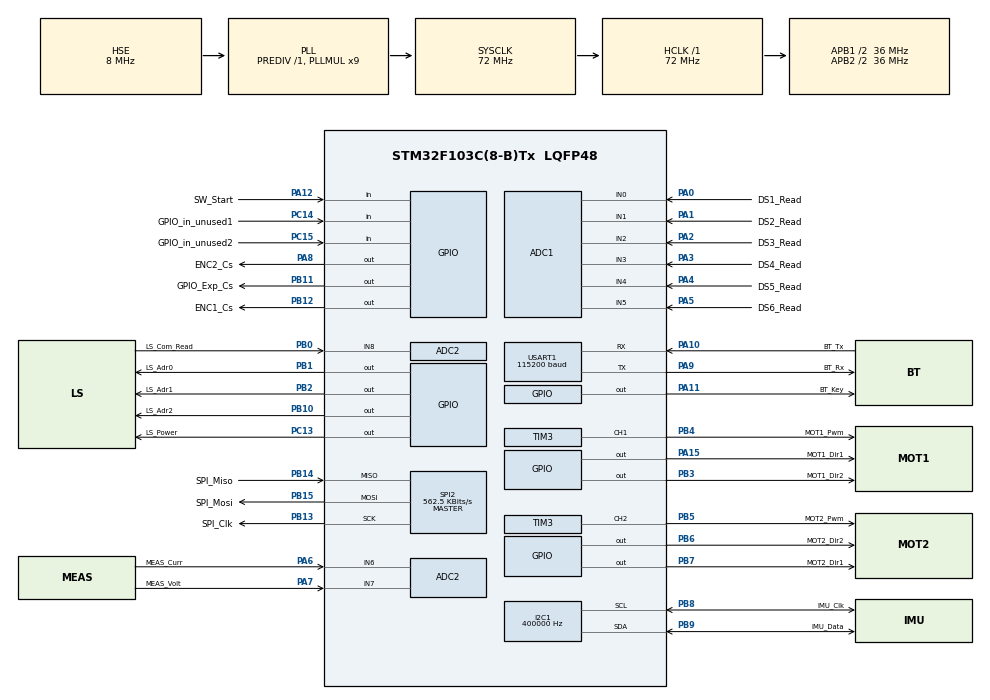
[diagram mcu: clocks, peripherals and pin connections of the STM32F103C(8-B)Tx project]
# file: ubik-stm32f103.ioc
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ADC1.Channel-48\#ChannelRegularConversion=ADC_CHANNEL_0
ADC1.Channel-49\#ChannelRegularConversion=ADC_CHANNEL_1
ADC1.Channel-50\#ChannelRegularConversion=ADC_CHANNEL_2
ADC1.Channel-51\#ChannelRegularConversion=ADC_CHANNEL_3
ADC1.Channel-52\#ChannelRegularConversion=ADC_CHANNEL_4
ADC1.Channel-53\#ChannelRegularConversion=ADC_CHANNEL_5
ADC1.ContinuousConvMode=DISABLE
ADC1.DataAlign=ADC_DATAALIGN_RIGHT
ADC1.DiscontinuousConvMode=DISABLE
ADC1.EnableAnalogWatchDog=false
ADC1.EnableRegularConversion=ENABLE
ADC1.ExternalTrigConv=ADC_SOFTWARE_START
ADC1.InjNumberOfConversion=0
ADC1.NbrOfConversion=6
ADC1.NbrOfConversionFlag=1
ADC1.Rank-48\#ChannelRegularConversion=1
ADC1.Rank-49\#ChannelRegularConversion=2
ADC1.Rank-50\#ChannelRegularConversion=3
ADC1.Rank-51\#ChannelRegularConversion=4
ADC1.Rank-52\#ChannelRegularConversion=5
ADC1.Rank-53\#ChannelRegularConversion=6
ADC1.SamplingTime-48\#ChannelRegularConversion=ADC_SAMPLETIME_28CYCLES_5
ADC1.SamplingTime-49\#ChannelRegularConversion=ADC_SAMPLETIME_28CYCLES_5
ADC1.SamplingTime-50\#ChannelRegularConversion=ADC_SAMPLETIME_28CYCLES_5
ADC1.SamplingTime-51\#ChannelRegularConversion=ADC_SAMPLETIME_28CYCLES_5
ADC1.SamplingTime-52\#ChannelRegularConversion=ADC_SAMPLETIME_28CYCLES_5
ADC1.SamplingTime-53\#ChannelRegularConversion=ADC_SAMPLETIME_28CYCLES_5
ADC1.ScanConvMode=ADC_SCAN_ENABLE
ADC1.master=1
ADC2.Channel-41\#ChannelRegularConversion=ADC_CHANNEL_6
ADC2.Channel-42\#ChannelRegularConversion=ADC_CHANNEL_7
ADC2.Channel-47\#ChannelInjectedConversion=ADC_CHANNEL_8
ADC2.ContinuousConvMode=DISABLE
ADC2.DataAlign=ADC_DATAALIGN_RIGHT
ADC2.DiscontinuousConvMode=ENABLE
ADC2.EnableAnalogWatchDog=false
ADC2.EnableRegularConversion=ENABLE
ADC2.ExternalTrigConv=ADC_SOFTWARE_START
ADC2.ExternalTrigInjecConv=ADC_INJECTED_SOFTWARE_START
ADC2.InjNumberOfConversion=1
ADC2.InjectedConvMode=None
ADC2.InjectedOffset-47\#ChannelInjectedConversion=0
ADC2.NbrOfConversion=2
ADC2.NbrOfConversionFlag=1
ADC2.NbrOfDiscConversion=1
ADC2.Rank-41\#ChannelRegularConversion=1
ADC2.Rank-42\#ChannelRegularConversion=2
ADC2.Rank-47\#ChannelInjectedConversion=1
ADC2.SamplingTime-41\#ChannelRegularConversion=ADC_SAMPLETIME_239CYCLES_5
ADC2.SamplingTime-42\#ChannelRegularConversion=ADC_SAMPLETIME_239CYCLES_5
ADC2.SamplingTime-47\#ChannelInjectedConversion=ADC_SAMPLETIME_13CYCLES_5
ADC2.ScanConvMode=ADC_SCAN_ENABLE
Dma.ADC1.2.Direction=DMA_PERIPH_TO_MEMORY
Dma.ADC1.2.Instance=DMA1_Channel1
Dma.ADC1.2.MemDataAlignment=DMA_MDATAALIGN_HALFWORD
Dma.ADC1.2.MemInc=DMA_MINC_ENABLE
Dma.ADC1.2.Mode=DMA_NORMAL
Dma.ADC1.2.PeriphDataAlignment=DMA_PDATAALIGN_HALFWORD
Dma.ADC1.2.PeriphInc=DMA_PINC_DISABLE
Dma.ADC1.2.Priority=DMA_PRIORITY_MEDIUM
Dma.I2C1_RX.0.Direction=DMA_PERIPH_TO_MEMORY
Dma.I2C1_RX.0.Instance=DMA1_Channel7
Dma.I2C1_RX.0.MemDataAlignment=DMA_MDATAALIGN_BYTE
Dma.I2C1_RX.0.MemInc=DMA_MINC_ENABLE
Dma.I2C1_RX.0.Mode=DMA_NORMAL
Dma.I2C1_RX.0.PeriphDataAlignment=DMA_PDATAALIGN_BYTE
Dma.I2C1_RX.0.PeriphInc=DMA_PINC_DISABLE
Dma.I2C1_RX.0.Priority=DMA_PRIORITY_HIGH
Dma.I2C1_TX.1.Direction=DMA_MEMORY_TO_PERIPH
Dma.I2C1_TX.1.Instance=DMA1_Channel6
Dma.I2C1_TX.1.MemDataAlignment=DMA_MDATAALIGN_BYTE
Dma.I2C1_TX.1.MemInc=DMA_MINC_ENABLE
Dma.I2C1_TX.1.Mode=DMA_NORMAL
Dma.I2C1_TX.1.PeriphDataAlignment=DMA_PDATAALIGN_BYTE
Dma.I2C1_TX.1.PeriphInc=DMA_PINC_DISABLE
Dma.I2C1_TX.1.Priority=DMA_PRIORITY_HIGH
Dma.Request0=I2C1_RX
Dma.Request1=I2C1_TX
Dma.Request2=ADC1
Dma.Request3=USART1_RX
Dma.Request4=USART1_TX
Dma.USART1_RX.3.Direction=DMA_PERIPH_TO_MEMORY
Dma.USART1_RX.3.Instance=DMA1_Channel5
Dma.USART1_RX.3.MemDataAlignment=DMA_MDATAALIGN_BYTE
Dma.USART1_RX.3.MemInc=DMA_MINC_ENABLE
Dma.USART1_RX.3.Mode=DMA_NORMAL
Dma.USART1_RX.3.PeriphDataAlignment=DMA_PDATAALIGN_BYTE
Dma.USART1_RX.3.PeriphInc=DMA_PINC_DISABLE
Dma.USART1_RX.3.Priority=DMA_PRIORITY_LOW
Dma.USART1_TX.4.Direction=DMA_MEMORY_TO_PERIPH
Dma.USART1_TX.4.Instance=DMA1_Channel4
Dma.USART1_TX.4.MemDataAlignment=DMA_MDATAALIGN_BYTE
Dma.USART1_TX.4.MemInc=DMA_MINC_ENABLE
Dma.USART1_TX.4.Mode=DMA_NORMAL
Dma.USART1_TX.4.PeriphDataAlignment=DMA_PDATAALIGN_BYTE
Dma.USART1_TX.4.PeriphInc=DMA_PINC_DISABLE
Dma.USART1_TX.4.Priority=DMA_PRIORITY_LOW
I2C1.ClockSpeed=400000
I2C1.DutyCycle=I2C_DUTYCYCLE_2
I2C1.I2C_Mode=I2C_Fast
Mcu.Family=STM32F1
Mcu.Name=STM32F103C(8-B)Tx
Mcu.Package=LQFP48
NVIC.DMA1_Channel1_IRQn=true\:7\:0\:true\:false\:true\:true
NVIC.DMA1_Channel4_IRQn=true\:9\:0\:true\:false\:true\:true
NVIC.DMA1_Channel5_IRQn=true\:9\:0\:true\:false\:true\:true
NVIC.DMA1_Channel6_IRQn=true\:6\:0\:true\:false\:true\:true
NVIC.DMA1_Channel7_IRQn=true\:6\:0\:true\:false\:true\:true
NVIC.PriorityGroup=NVIC_PRIORITYGROUP_4
NVIC.TIM1_UP_IRQn=true\:0\:0\:false\:false\:true\:true
NVIC.TIM2_IRQn=true\:7\:0\:true\:false\:true\:true
NVIC.TIM4_IRQn=true\:8\:0\:true\:false\:true\:true
NVIC.TimeBase=TIM1_UP_IRQn
NVIC.TimeBaseIP=TIM1
NVIC.USART1_IRQn=true\:10\:0\:true\:false\:true\:true
PA0-WKUP.GPIO_Label=DS1_Read
PA0-WKUP.Signal=ADCx_IN0
PA1.GPIO_Label=DS2_Read
PA1.Signal=ADCx_IN1
PA10.GPIO_Label=BT_Tx
PA10.Mode=Asynchronous
PA10.Signal=USART1_RX
PA11.GPIO_Label=BT_Key
PA11.PinState=GPIO_PIN_SET
PA11.Signal=GPIO_Output
PA12.GPIO_Label=SW_Start
PA12.GPIO_PuPd=GPIO_PULLDOWN
PA12.Signal=GPIO_Input
PA13.GPIO_Label=SWD_IO
PA13.Mode=Serial_Wire
PA13.Signal=SYS_JTMS-SWDIO
PA14.GPIO_Label=SDW_CLK
PA14.Mode=Serial_Wire
PA14.Signal=SYS_JTCK-SWCLK
PA15.GPIO_Label=MOT1_Dir1
PA15.Signal=GPIO_Output
PA2.GPIO_Label=DS3_Read
PA2.Signal=ADCx_IN2
PA3.GPIO_Label=DS4_Read
PA3.Signal=ADCx_IN3
PA4.GPIO_Label=DS5_Read
PA4.Signal=ADCx_IN4
PA5.GPIO_Label=DS6_Read
PA5.Signal=ADCx_IN5
PA6.GPIO_Label=MEAS_Curr
PA6.Signal=ADCx_IN6
PA7.GPIO_Label=MEAS_Volt
PA7.Signal=ADCx_IN7
PA8.GPIO_Label=ENC2_Cs
PA8.GPIO_Speed=GPIO_SPEED_FREQ_HIGH
PA8.PinState=GPIO_PIN_SET
PA8.Signal=GPIO_Output
PA9.GPIO_Label=BT_Rx
PA9.Mode=Asynchronous
PA9.Signal=USART1_TX
PB0.GPIO_Label=LS_Com_Read
PB0.Signal=ADCx_IN8
PB1.GPIO_Label=LS_Adr0
PB1.Signal=GPIO_Output
PB10.GPIO_Label=LS_Adr2
PB10.Signal=GPIO_Output
PB11.GPIO_Label=GPIO_Exp_Cs
PB11.GPIO_Speed=GPIO_SPEED_FREQ_HIGH
PB11.PinState=GPIO_PIN_SET
PB11.Signal=GPIO_Output
PB12.GPIO_Label=ENC1_Cs
PB12.PinState=GPIO_PIN_SET
PB12.Signal=GPIO_Output
PB13.GPIO_Label=SPI_Clk
PB13.Mode=Full_Duplex_Master
PB13.Signal=SPI2_SCK
PB14.GPIO_Label=SPI_Miso
PB14.Mode=Full_Duplex_Master
PB14.Signal=SPI2_MISO
PB15.GPIO_Label=SPI_Mosi
PB15.Mode=Full_Duplex_Master
PB15.Signal=SPI2_MOSI
PB2.GPIO_Label=LS_Adr1
PB2.Signal=GPIO_Output
PB3.GPIO_Label=MOT1_Dir2
PB3.Signal=GPIO_Output
PB4.GPIO_Label=MOT1_Pwm
PB4.Signal=S_TIM3_CH1
PB5.GPIO_Label=MOT2_Pwm
PB5.GPIO_Speed=GPIO_SPEED_FREQ_LOW
PB5.Signal=S_TIM3_CH2
PB6.GPIO_Label=MOT2_Dir2
PB6.Signal=GPIO_Output
PB7.GPIO_Label=MOT2_Dir1
PB7.Signal=GPIO_Output
PB8.GPIO_Label=IMU_Clk
PB8.Mode=I2C
PB8.Signal=I2C1_SCL
PB9.GPIO_Label=IMU_Data
PB9.Mode=I2C
PB9.Signal=I2C1_SDA
PC13-TAMPER-RTC.GPIO_Label=LS_Power
PC13-TAMPER-RTC.Signal=GPIO_Output
PC14-OSC32_IN.GPIO_Label=GPIO_in_unused1
PC14-OSC32_IN.GPIO_PuPd=GPIO_PULLUP
PC14-OSC32_IN.Signal=GPIO_Input
PC15-OSC32_OUT.GPIO_Label=GPIO_in_unused2
PC15-OSC32_OUT.GPIO_PuPd=GPIO_PULLUP
PC15-OSC32_OUT.Signal=GPIO_Input
PD0-OSC_IN.Mode=HSE-External-Oscillator
PD0-OSC_IN.Signal=RCC_OSC_IN
PD1-OSC_OUT.Mode=HSE-External-Oscillator
PD1-OSC_OUT.Signal=RCC_OSC_OUT
ProjectManager.HeapSize=0x200
ProjectManager.StackSize=0x400
ProjectManager.TargetToolchain=SW4STM32
RCC.ADCPresc=RCC_ADCPCLK2_DIV4
RCC.AHBFreq_Value=72000000
RCC.APB1CLKDivider=RCC_HCLK_DIV2
RCC.APB1Freq_Value=36000000
RCC.APB1TimFreq_Value=72000000
RCC.APB2CLKDivider=RCC_HCLK_DIV2
RCC.APB2Freq_Value=36000000
RCC.APB2TimFreq_Value=72000000
RCC.HCLKFreq_Value=72000000
RCC.PLLMUL=RCC_PLL_MUL9
RCC.PLLSourceVirtual=RCC_PLLSOURCE_HSE
RCC.SYSCLKFreq_VALUE=72000000
RCC.SYSCLKSource=RCC_SYSCLKSOURCE_PLLCLK
RCC.USBFreq_Value=72000000
RCC.VDD_VALUE=3.3
SH.ADCx_IN0.0=ADC1_IN0,IN0
SH.ADCx_IN1.0=ADC1_IN1,IN1
SH.ADCx_IN2.0=ADC1_IN2,IN2
SH.ADCx_IN3.0=ADC1_IN3,IN3
SH.ADCx_IN4.0=ADC1_IN4,IN4
SH.ADCx_IN5.0=ADC1_IN5,IN5
SH.ADCx_IN6.0=ADC2_IN6,IN6
SH.ADCx_IN7.0=ADC2_IN7,IN7
SH.ADCx_IN8.0=ADC2_IN8,IN8
SH.S_TIM3_CH1.0=TIM3_CH1,PWM Generation1 CH1
SH.S_TIM3_CH2.0=TIM3_CH2,PWM Generation2 CH2
SPI2.BaudRatePrescaler=SPI_BAUDRATEPRESCALER_64
SPI2.CLKPhase=SPI_PHASE_1EDGE
SPI2.CLKPolarity=SPI_POLARITY_HIGH
SPI2.CalculateBaudRate=562.5 KBits/s
SPI2.Direction=SPI_DIRECTION_2LINES
SPI2.Mode=SPI_MODE_MASTER
SPI2.VirtualType=VM_MASTER
TIM2.Prescaler=72 - 1
TIM2.TIM_MasterOutputTrigger=TIM_TRGO_RESET
TIM3.Channel-PWM\ Generation1\ CH1=TIM_CHANNEL_1
TIM3.Channel-PWM\ Generation2\ CH2=TIM_CHANNEL_2
TIM3.Period=7200 - 1
TIM3.Prescaler=0
TIM4.Period=250 - 1
TIM4.Prescaler=72 - 1
USART1.BaudRate=115200
USART1.VirtualMode=VM_ASYNC
VP_SYS_VS_tim1.Mode=TIM1
VP_TIM2_VS_ClockSourceINT.Mode=Internal
VP_TIM4_VS_ClockSourceINT.Mode=Internal
board=ubik-stm32f103

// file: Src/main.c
/**
  ******************************************************************************
  * @file           : main.c
  * @brief          : Main program body
  ******************************************************************************
  ** This notice applies to any and all portions of this file
  * that are not between comment pairs USER CODE BEGIN and
  * USER CODE END. Other portions of this file, whether
  * inserted by the user or by software development tools
  * are owned by their respective copyright owners.
  *
  * COPYRIGHT(c) 2018 STMicroelectronics
  *
  * Redistribution and use in source and binary forms, with or without modification,
  * are permitted provided that the following conditions are met:
  *   1. Redistributions of source code must retain the above copyright notice,
  *      this list of conditions and the following disclaimer.
  *   2. Redistributions in binary form must reproduce the above copyright notice,
  *      this list of conditions and the following disclaimer in the documentation
  *      and/or other materials provided with the distribution.
  *   3. Neither the name of STMicroelectronics nor the names of its contributors
  *      may be used to endorse or promote products derived from this software
  *      without specific prior written permission.
  *
  * THIS SOFTWARE IS PROVIDED BY THE COPYRIGHT HOLDERS AND CONTRIBUTORS "AS IS"
  * AND ANY EXPRESS OR IMPLIED WARRANTIES, INCLUDING, BUT NOT LIMITED TO, THE
  * IMPLIED WARRANTIES OF MERCHANTABILITY AND FITNESS FOR A PARTICULAR PURPOSE ARE
  * DISCLAIMED. IN NO EVENT SHALL THE COPYRIGHT HOLDER OR CONTRIBUTORS BE LIABLE
  * FOR ANY DIRECT, INDIRECT, INCIDENTAL, SPECIAL, EXEMPLARY, OR CONSEQUENTIAL
  * DAMAGES (INCLUDING, BUT NOT LIMITED TO, PROCUREMENT OF SUBSTITUTE GOODS OR
  * SERVICES; LOSS OF USE, DATA, OR PROFITS; OR BUSINESS INTERRUPTION) HOWEVER
  * CAUSED AND ON ANY THEORY OF LIABILITY, WHETHER IN CONTRACT, STRICT LIABILITY,
  * OR TORT (INCLUDING NEGLIGENCE OR OTHERWISE) ARISING IN ANY WAY OUT OF THE USE
  * OF THIS SOFTWARE, EVEN IF ADVISED OF THE POSSIBILITY OF SUCH DAMAGE.
  *
  ******************************************************************************
  */
#include "main.h"
#include "stm32f1xx_hal.h"

ADC_HandleTypeDef hadc1;
ADC_HandleTypeDef hadc2;
DMA_HandleTypeDef hdma_adc1;

I2C_HandleTypeDef hi2c1;
DMA_HandleTypeDef hdma_i2c1_rx;
DMA_HandleTypeDef hdma_i2c1_tx;

SPI_HandleTypeDef hspi2;

TIM_HandleTypeDef htim2;
TIM_HandleTypeDef htim3;
TIM_HandleTypeDef htim4;

UART_HandleTypeDef huart1;
DMA_HandleTypeDef hdma_usart1_rx;
DMA_HandleTypeDef hdma_usart1_tx;

/* USER CODE BEGIN PV */
/* Private variables ---------------------------------------------------------*/

/* USER CODE END PV */

void SystemClock_Config(void);
static void MX_GPIO_Init(void);
static void MX_DMA_Init(void);
static void MX_SPI2_Init(void);
static void MX_TIM3_Init(void);
static void MX_USART1_UART_Init(void);
static void MX_ADC2_Init(void);
static void MX_ADC1_Init(void);
static void MX_TIM2_Init(void);
static void MX_I2C1_Init(void);
static void MX_TIM4_Init(void);

void HAL_TIM_MspPostInit(TIM_HandleTypeDef *htim);

/* USER CODE BEGIN PFP */
/* Private function prototypes -----------------------------------------------*/

/* USER CODE END PFP */

int main(void)
{

  /* MCU Configuration----------------------------------------------------------*/

  /* Reset of all peripherals, Initializes the Flash interface and the Systick. */
  HAL_Init();

  /* Configure the system clock */
  SystemClock_Config();

   /* USER CODE BEGIN SysInit */

  /* Disable SysTick before it shoots!
   *
   * In FreeRTOSConfig.h SysTick_Handler is mapped to xPortSysTickHandler
   * so we cannot let SysTick fire its interrupt before starting FreeRTOS
   * scheduler. In Cube we changed System Timebase to some other timer, so
   * we can safely disable SysTick here. FreeRTOS will configure it when
   * it starts.  */
  CLEAR_BIT(SysTick->CTRL, SysTick_CTRL_ENABLE_Msk);

  /* USER CODE END SysInit */

  /* Initialize all configured peripherals */
  MX_GPIO_Init();
  MX_DMA_Init();
  MX_SPI2_Init();
  MX_TIM3_Init();
  MX_USART1_UART_Init();
  MX_ADC2_Init();
  MX_ADC1_Init();
  MX_TIM2_Init();
  MX_I2C1_Init();
  MX_TIM4_Init();
  /* USER CODE BEGIN 2 */

  /* Pass control to extern_main() defined somewhere else with C linkage */
  extern void extern_main(void);
  extern_main();

  /* Execution should never get here */
  Error_Handler();

  /* USER CODE END 2 */

  /* Infinite loop */
  while (1)
  {

  }

}

void SystemClock_Config(void)
{

  RCC_OscInitTypeDef RCC_OscInitStruct;
  RCC_ClkInitTypeDef RCC_ClkInitStruct;
  RCC_PeriphCLKInitTypeDef PeriphClkInit;

    /**Initializes the CPU, AHB and APB busses clocks
    */
  RCC_OscInitStruct.OscillatorType = RCC_OSCILLATORTYPE_HSE;
  RCC_OscInitStruct.HSEState = RCC_HSE_ON;
  RCC_OscInitStruct.HSEPredivValue = RCC_HSE_PREDIV_DIV1;
  RCC_OscInitStruct.HSIState = RCC_HSI_ON;
  RCC_OscInitStruct.PLL.PLLState = RCC_PLL_ON;
  RCC_OscInitStruct.PLL.PLLSource = RCC_PLLSOURCE_HSE;
  RCC_OscInitStruct.PLL.PLLMUL = RCC_PLL_MUL9;
  if (HAL_RCC_OscConfig(&RCC_OscInitStruct) != HAL_OK)
  {
    _Error_Handler(__FILE__, __LINE__);
  }

    /**Initializes the CPU, AHB and APB busses clocks
    */
  RCC_ClkInitStruct.ClockType = RCC_CLOCKTYPE_HCLK|RCC_CLOCKTYPE_SYSCLK
                              |RCC_CLOCKTYPE_PCLK1|RCC_CLOCKTYPE_PCLK2;
  RCC_ClkInitStruct.SYSCLKSource = RCC_SYSCLKSOURCE_PLLCLK;
  RCC_ClkInitStruct.AHBCLKDivider = RCC_SYSCLK_DIV1;
  RCC_ClkInitStruct.APB1CLKDivider = RCC_HCLK_DIV2;
  RCC_ClkInitStruct.APB2CLKDivider = RCC_HCLK_DIV2;

  if (HAL_RCC_ClockConfig(&RCC_ClkInitStruct, FLASH_LATENCY_2) != HAL_OK)
  {
    _Error_Handler(__FILE__, __LINE__);
  }

  PeriphClkInit.PeriphClockSelection = RCC_PERIPHCLK_ADC;
  PeriphClkInit.AdcClockSelection = RCC_ADCPCLK2_DIV4;
  if (HAL_RCCEx_PeriphCLKConfig(&PeriphClkInit) != HAL_OK)
  {
    _Error_Handler(__FILE__, __LINE__);
  }

    /**Configure the Systick interrupt time
    */
  HAL_SYSTICK_Config(HAL_RCC_GetHCLKFreq()/1000);

    /**Configure the Systick
    */
  HAL_SYSTICK_CLKSourceConfig(SYSTICK_CLKSOURCE_HCLK);

  /* SysTick_IRQn interrupt configuration */
  HAL_NVIC_SetPriority(SysTick_IRQn, 0, 0);
}

/* ADC1 init function */
static void MX_ADC1_Init(void)
{

  ADC_ChannelConfTypeDef sConfig;

    /**Common config
    */
  hadc1.Instance = ADC1;
  hadc1.Init.ScanConvMode = ADC_SCAN_ENABLE;
  hadc1.Init.ContinuousConvMode = DISABLE;
  hadc1.Init.DiscontinuousConvMode = DISABLE;
  hadc1.Init.ExternalTrigConv = ADC_SOFTWARE_START;
  hadc1.Init.DataAlign = ADC_DATAALIGN_RIGHT;
  hadc1.Init.NbrOfConversion = 6;
  if (HAL_ADC_Init(&hadc1) != HAL_OK)
  {
    _Error_Handler(__FILE__, __LINE__);
  }

    /**Configure Regular Channel
    */
  sConfig.Channel = ADC_CHANNEL_0;
  sConfig.Rank = ADC_REGULAR_RANK_1;
  sConfig.SamplingTime = ADC_SAMPLETIME_28CYCLES_5;
  if (HAL_ADC_ConfigChannel(&hadc1, &sConfig) != HAL_OK)
  {
    _Error_Handler(__FILE__, __LINE__);
  }

    /**Configure Regular Channel
    */
  sConfig.Channel = ADC_CHANNEL_1;
  sConfig.Rank = ADC_REGULAR_RANK_2;
  if (HAL_ADC_ConfigChannel(&hadc1, &sConfig) != HAL_OK)
  {
    _Error_Handler(__FILE__, __LINE__);
  }

    /**Configure Regular Channel
    */
  sConfig.Channel = ADC_CHANNEL_2;
  sConfig.Rank = ADC_REGULAR_RANK_3;
  if (HAL_ADC_ConfigChannel(&hadc1, &sConfig) != HAL_OK)
  {
    _Error_Handler(__FILE__, __LINE__);
  }

    /**Configure Regular Channel
    */
  sConfig.Channel = ADC_CHANNEL_3;
  sConfig.Rank = ADC_REGULAR_RANK_4;
  if (HAL_ADC_ConfigChannel(&hadc1, &sConfig) != HAL_OK)
  {
    _Error_Handler(__FILE__, __LINE__);
  }

    /**Configure Regular Channel
    */
  sConfig.Channel = ADC_CHANNEL_4;
  sConfig.Rank = ADC_REGULAR_RANK_5;
  if (HAL_ADC_ConfigChannel(&hadc1, &sConfig) != HAL_OK)
  {
    _Error_Handler(__FILE__, __LINE__);
  }

    /**Configure Regular Channel
    */
  sConfig.Channel = ADC_CHANNEL_5;
  sConfig.Rank = ADC_REGULAR_RANK_6;
  if (HAL_ADC_ConfigChannel(&hadc1, &sConfig) != HAL_OK)
  {
    _Error_Handler(__FILE__, __LINE__);
  }

}

/* ADC2 init function */
static void MX_ADC2_Init(void)
{

  ADC_ChannelConfTypeDef sConfig;
  ADC_InjectionConfTypeDef sConfigInjected;

    /**Common config
    */
  hadc2.Instance = ADC2;
  hadc2.Init.ScanConvMode = ADC_SCAN_ENABLE;
  hadc2.Init.ContinuousConvMode = DISABLE;
  hadc2.Init.DiscontinuousConvMode = ENABLE;
  hadc2.Init.NbrOfDiscConversion = 1;
  hadc2.Init.ExternalTrigConv = ADC_SOFTWARE_START;
  hadc2.Init.DataAlign = ADC_DATAALIGN_RIGHT;
  hadc2.Init.NbrOfConversion = 2;
  if (HAL_ADC_Init(&hadc2) != HAL_OK)
  {
    _Error_Handler(__FILE__, __LINE__);
  }

    /**Configure Regular Channel
    */
  sConfig.Channel = ADC_CHANNEL_6;
  sConfig.Rank = ADC_REGULAR_RANK_1;
  sConfig.SamplingTime = ADC_SAMPLETIME_239CYCLES_5;
  if (HAL_ADC_ConfigChannel(&hadc2, &sConfig) != HAL_OK)
  {
    _Error_Handler(__FILE__, __LINE__);
  }

    /**Configure Regular Channel
    */
  sConfig.Channel = ADC_CHANNEL_7;
  sConfig.Rank = ADC_REGULAR_RANK_2;
  if (HAL_ADC_ConfigChannel(&hadc2, &sConfig) != HAL_OK)
  {
    _Error_Handler(__FILE__, __LINE__);
  }

    /**Configure Injected Channel
    */
  sConfigInjected.InjectedChannel = ADC_CHANNEL_8;
  sConfigInjected.InjectedRank = ADC_INJECTED_RANK_1;
  sConfigInjected.InjectedNbrOfConversion = 1;
  sConfigInjected.InjectedSamplingTime = ADC_SAMPLETIME_13CYCLES_5;
  sConfigInjected.ExternalTrigInjecConv = ADC_INJECTED_SOFTWARE_START;
  sConfigInjected.AutoInjectedConv = DISABLE;
  sConfigInjected.InjectedDiscontinuousConvMode = DISABLE;
  sConfigInjected.InjectedOffset = 0;
  if (HAL_ADCEx_InjectedConfigChannel(&hadc2, &sConfigInjected) != HAL_OK)
  {
    _Error_Handler(__FILE__, __LINE__);
  }

}

/* I2C1 init function */
static void MX_I2C1_Init(void)
{

  hi2c1.Instance = I2C1;
  hi2c1.Init.ClockSpeed = 400000;
  hi2c1.Init.DutyCycle = I2C_DUTYCYCLE_2;
  hi2c1.Init.OwnAddress1 = 0;
  hi2c1.Init.AddressingMode = I2C_ADDRESSINGMODE_7BIT;
  hi2c1.Init.DualAddressMode = I2C_DUALADDRESS_DISABLE;
  hi2c1.Init.OwnAddress2 = 0;
  hi2c1.Init.GeneralCallMode = I2C_GENERALCALL_DISABLE;
  hi2c1.Init.NoStretchMode = I2C_NOSTRETCH_DISABLE;
  if (HAL_I2C_Init(&hi2c1) != HAL_OK)
  {
    _Error_Handler(__FILE__, __LINE__);
  }

}

/* SPI2 init function */
static void MX_SPI2_Init(void)
{

  /* SPI2 parameter configuration*/
  hspi2.Instance = SPI2;
  hspi2.Init.Mode = SPI_MODE_MASTER;
  hspi2.Init.Direction = SPI_DIRECTION_2LINES;
  hspi2.Init.DataSize = SPI_DATASIZE_8BIT;
  hspi2.Init.CLKPolarity = SPI_POLARITY_HIGH;
  hspi2.Init.CLKPhase = SPI_PHASE_1EDGE;
  hspi2.Init.NSS = SPI_NSS_SOFT;
  hspi2.Init.BaudRatePrescaler = SPI_BAUDRATEPRESCALER_64;
  hspi2.Init.FirstBit = SPI_FIRSTBIT_MSB;
  hspi2.Init.TIMode = SPI_TIMODE_DISABLE;
  hspi2.Init.CRCCalculation = SPI_CRCCALCULATION_DISABLE;
  hspi2.Init.CRCPolynomial = 10;
  if (HAL_SPI_Init(&hspi2) != HAL_OK)
  {
    _Error_Handler(__FILE__, __LINE__);
  }

}

/* TIM2 init function */
static void MX_TIM2_Init(void)
{

  TIM_ClockConfigTypeDef sClockSourceConfig;
  TIM_MasterConfigTypeDef sMasterConfig;

  htim2.Instance = TIM2;
  htim2.Init.Prescaler = 72 - 1;
  htim2.Init.CounterMode = TIM_COUNTERMODE_UP;
  htim2.Init.Period = 0;
  htim2.Init.ClockDivision = TIM_CLOCKDIVISION_DIV1;
  htim2.Init.AutoReloadPreload = TIM_AUTORELOAD_PRELOAD_DISABLE;
  if (HAL_TIM_Base_Init(&htim2) != HAL_OK)
  {
    _Error_Handler(__FILE__, __LINE__);
  }

  sClockSourceConfig.ClockSource = TIM_CLOCKSOURCE_INTERNAL;
  if (HAL_TIM_ConfigClockSource(&htim2, &sClockSourceConfig) != HAL_OK)
  {
    _Error_Handler(__FILE__, __LINE__);
  }

  sMasterConfig.MasterOutputTrigger = TIM_TRGO_RESET;
  sMasterConfig.MasterSlaveMode = TIM_MASTERSLAVEMODE_DISABLE;
  if (HAL_TIMEx_MasterConfigSynchronization(&htim2, &sMasterConfig) != HAL_OK)
  {
    _Error_Handler(__FILE__, __LINE__);
  }

}

/* TIM3 init function */
static void MX_TIM3_Init(void)
{

  TIM_MasterConfigTypeDef sMasterConfig;
  TIM_OC_InitTypeDef sConfigOC;

  htim3.Instance = TIM3;
  htim3.Init.Prescaler = 0;
  htim3.Init.CounterMode = TIM_COUNTERMODE_UP;
  htim3.Init.Period = 7200 - 1;
  htim3.Init.ClockDivision = TIM_CLOCKDIVISION_DIV1;
  htim3.Init.AutoReloadPreload = TIM_AUTORELOAD_PRELOAD_DISABLE;
  if (HAL_TIM_PWM_Init(&htim3) != HAL_OK)
  {
    _Error_Handler(__FILE__, __LINE__);
  }

  sMasterConfig.MasterOutputTrigger = TIM_TRGO_RESET;
  sMasterConfig.MasterSlaveMode = TIM_MASTERSLAVEMODE_DISABLE;
  if (HAL_TIMEx_MasterConfigSynchronization(&htim3, &sMasterConfig) != HAL_OK)
  {
    _Error_Handler(__FILE__, __LINE__);
  }

  sConfigOC.OCMode = TIM_OCMODE_PWM1;
  sConfigOC.Pulse = 0;
  sConfigOC.OCPolarity = TIM_OCPOLARITY_HIGH;
  sConfigOC.OCFastMode = TIM_OCFAST_DISABLE;
  if (HAL_TIM_PWM_ConfigChannel(&htim3, &sConfigOC, TIM_CHANNEL_1) != HAL_OK)
  {
    _Error_Handler(__FILE__, __LINE__);
  }

  if (HAL_TIM_PWM_ConfigChannel(&htim3, &sConfigOC, TIM_CHANNEL_2) != HAL_OK)
  {
    _Error_Handler(__FILE__, __LINE__);
  }

  HAL_TIM_MspPostInit(&htim3);

}

/* TIM4 init function */
static void MX_TIM4_Init(void)
{

  TIM_ClockConfigTypeDef sClockSourceConfig;
  TIM_MasterConfigTypeDef sMasterConfig;

  htim4.Instance = TIM4;
  htim4.Init.Prescaler = 72 - 1;
  htim4.Init.CounterMode = TIM_COUNTERMODE_UP;
  htim4.Init.Period = 250 - 1;
  htim4.Init.ClockDivision = TIM_CLOCKDIVISION_DIV1;
  htim4.Init.AutoReloadPreload = TIM_AUTORELOAD_PRELOAD_DISABLE;
  if (HAL_TIM_Base_Init(&htim4) != HAL_OK)
  {
    _Error_Handler(__FILE__, __LINE__);
  }

  sClockSourceConfig.ClockSource = TIM_CLOCKSOURCE_INTERNAL;
  if (HAL_TIM_ConfigClockSource(&htim4, &sClockSourceConfig) != HAL_OK)
  {
    _Error_Handler(__FILE__, __LINE__);
  }

  sMasterConfig.MasterOutputTrigger = TIM_TRGO_RESET;
  sMasterConfig.MasterSlaveMode = TIM_MASTERSLAVEMODE_DISABLE;
  if (HAL_TIMEx_MasterConfigSynchronization(&htim4, &sMasterConfig) != HAL_OK)
  {
    _Error_Handler(__FILE__, __LINE__);
  }

}

/* USART1 init function */
static void MX_USART1_UART_Init(void)
{

  huart1.Instance = USART1;
  huart1.Init.BaudRate = 115200;
  huart1.Init.WordLength = UART_WORDLENGTH_8B;
  huart1.Init.StopBits = UART_STOPBITS_1;
  huart1.Init.Parity = UART_PARITY_NONE;
  huart1.Init.Mode = UART_MODE_TX_RX;
  huart1.Init.HwFlowCtl = UART_HWCONTROL_NONE;
  huart1.Init.OverSampling = UART_OVERSAMPLING_16;
  if (HAL_UART_Init(&huart1) != HAL_OK)
  {
    _Error_Handler(__FILE__, __LINE__);
  }

}

static void MX_DMA_Init(void)
{
  /* DMA controller clock enable */
  __HAL_RCC_DMA1_CLK_ENABLE();

  /* DMA interrupt init */
  /* DMA1_Channel1_IRQn interrupt configuration */
  HAL_NVIC_SetPriority(DMA1_Channel1_IRQn, 7, 0);
  HAL_NVIC_EnableIRQ(DMA1_Channel1_IRQn);
  /* DMA1_Channel4_IRQn interrupt configuration */
  HAL_NVIC_SetPriority(DMA1_Channel4_IRQn, 9, 0);
  HAL_NVIC_EnableIRQ(DMA1_Channel4_IRQn);
  /* DMA1_Channel5_IRQn interrupt configuration */
  HAL_NVIC_SetPriority(DMA1_Channel5_IRQn, 9, 0);
  HAL_NVIC_EnableIRQ(DMA1_Channel5_IRQn);
  /* DMA1_Channel6_IRQn interrupt configuration */
  HAL_NVIC_SetPriority(DMA1_Channel6_IRQn, 6, 0);
  HAL_NVIC_EnableIRQ(DMA1_Channel6_IRQn);
  /* DMA1_Channel7_IRQn interrupt configuration */
  HAL_NVIC_SetPriority(DMA1_Channel7_IRQn, 6, 0);
  HAL_NVIC_EnableIRQ(DMA1_Channel7_IRQn);

}

/** Configure pins as
        * Analog
        * Input
        * Output
        * EVENT_OUT
        * EXTI
*/
static void MX_GPIO_Init(void)
{

  GPIO_InitTypeDef GPIO_InitStruct;

  /* GPIO Ports Clock Enable */
  __HAL_RCC_GPIOC_CLK_ENABLE();
  __HAL_RCC_GPIOD_CLK_ENABLE();
  __HAL_RCC_GPIOA_CLK_ENABLE();
  __HAL_RCC_GPIOB_CLK_ENABLE();

  /*Configure GPIO pin Output Level */
  HAL_GPIO_WritePin(LS_Power_GPIO_Port, LS_Power_Pin, GPIO_PIN_RESET);

  /*Configure GPIO pin Output Level */
  HAL_GPIO_WritePin(GPIOB, LS_Adr0_Pin|LS_Adr1_Pin|LS_Adr2_Pin|MOT1_Dir2_Pin
                          |MOT2_Dir2_Pin|MOT2_Dir1_Pin, GPIO_PIN_RESET);

  /*Configure GPIO pin Output Level */
  HAL_GPIO_WritePin(GPIOB, GPIO_Exp_Cs_Pin|ENC1_Cs_Pin, GPIO_PIN_SET);

  /*Configure GPIO pin Output Level */
  HAL_GPIO_WritePin(GPIOA, ENC2_Cs_Pin|BT_Key_Pin, GPIO_PIN_SET);

  /*Configure GPIO pin Output Level */
  HAL_GPIO_WritePin(MOT1_Dir1_GPIO_Port, MOT1_Dir1_Pin, GPIO_PIN_RESET);

  /*Configure GPIO pin : LS_Power_Pin */
  GPIO_InitStruct.Pin = LS_Power_Pin;
  GPIO_InitStruct.Mode = GPIO_MODE_OUTPUT_PP;
  GPIO_InitStruct.Pull = GPIO_NOPULL;
  GPIO_InitStruct.Speed = GPIO_SPEED_FREQ_LOW;
  HAL_GPIO_Init(LS_Power_GPIO_Port, &GPIO_InitStruct);

  /*Configure GPIO pins : GPIO_in_unused1_Pin GPIO_in_unused2_Pin */
  GPIO_InitStruct.Pin = GPIO_in_unused1_Pin|GPIO_in_unused2_Pin;
  GPIO_InitStruct.Mode = GPIO_MODE_INPUT;
  GPIO_InitStruct.Pull = GPIO_PULLUP;
  HAL_GPIO_Init(GPIOC, &GPIO_InitStruct);

  /*Configure GPIO pins : LS_Adr0_Pin LS_Adr1_Pin LS_Adr2_Pin ENC1_Cs_Pin
                           MOT1_Dir2_Pin MOT2_Dir2_Pin MOT2_Dir1_Pin */
  GPIO_InitStruct.Pin = LS_Adr0_Pin|LS_Adr1_Pin|LS_Adr2_Pin|ENC1_Cs_Pin
                          |MOT1_Dir2_Pin|MOT2_Dir2_Pin|MOT2_Dir1_Pin;
  GPIO_InitStruct.Mode = GPIO_MODE_OUTPUT_PP;
  GPIO_InitStruct.Pull = GPIO_NOPULL;
  GPIO_InitStruct.Speed = GPIO_SPEED_FREQ_LOW;
  HAL_GPIO_Init(GPIOB, &GPIO_InitStruct);

  /*Configure GPIO pin : GPIO_Exp_Cs_Pin */
  GPIO_InitStruct.Pin = GPIO_Exp_Cs_Pin;
  GPIO_InitStruct.Mode = GPIO_MODE_OUTPUT_PP;
  GPIO_InitStruct.Pull = GPIO_NOPULL;
  GPIO_InitStruct.Speed = GPIO_SPEED_FREQ_HIGH;
  HAL_GPIO_Init(GPIO_Exp_Cs_GPIO_Port, &GPIO_InitStruct);

  /*Configure GPIO pin : ENC2_Cs_Pin */
  GPIO_InitStruct.Pin = ENC2_Cs_Pin;
  GPIO_InitStruct.Mode = GPIO_MODE_OUTPUT_PP;
  GPIO_InitStruct.Pull = GPIO_NOPULL;
  GPIO_InitStruct.Speed = GPIO_SPEED_FREQ_HIGH;
  HAL_GPIO_Init(ENC2_Cs_GPIO_Port, &GPIO_InitStruct);

  /*Configure GPIO pins : BT_Key_Pin MOT1_Dir1_Pin */
  GPIO_InitStruct.Pin = BT_Key_Pin|MOT1_Dir1_Pin;
  GPIO_InitStruct.Mode = GPIO_MODE_OUTPUT_PP;
  GPIO_InitStruct.Pull = GPIO_NOPULL;
  GPIO_InitStruct.Speed = GPIO_SPEED_FREQ_LOW;
  HAL_GPIO_Init(GPIOA, &GPIO_InitStruct);

  /*Configure GPIO pin : SW_Start_Pin */
  GPIO_InitStruct.Pin = SW_Start_Pin;
  GPIO_InitStruct.Mode = GPIO_MODE_INPUT;
  GPIO_InitStruct.Pull = GPIO_PULLDOWN;
  HAL_GPIO_Init(SW_Start_GPIO_Port, &GPIO_InitStruct);

}

void HAL_TIM_PeriodElapsedCallback(TIM_HandleTypeDef *htim)
{
  if (htim->Instance == TIM1) {
    HAL_IncTick();
  }
   /* USER CODE BEGIN Callback 1 */

  extern void callback_timer_period_elapsed(TIM_HandleTypeDef *htim);
  callback_timer_period_elapsed(htim);

  /* USER CODE END Callback 1 */
}

void _Error_Handler(char *file, int line)
{
  while(1)
  {
  }
}

/************************ (C) COPYRIGHT STMicroelectronics *****END OF FILE****/
